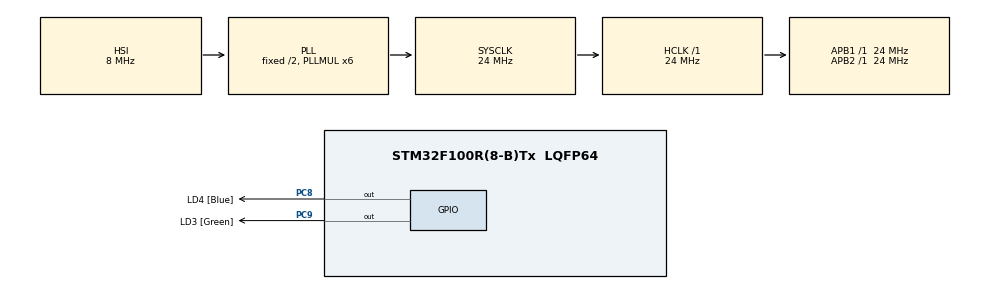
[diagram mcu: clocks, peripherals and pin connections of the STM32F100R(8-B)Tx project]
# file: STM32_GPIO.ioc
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Mcu.Family=STM32F1
Mcu.Name=STM32F100R(8-B)Tx
Mcu.Package=LQFP64
NVIC.PriorityGroup=NVIC_PRIORITYGROUP_4
PA0-WKUP.Signal=SYS_WKUP
PA13.GPIO_Label=TMS_SWDIO
PA13.Signal=SYS_JTMS-SWDIO
PA14.GPIO_Label=TCK_SWCLK
PA14.Signal=SYS_JTCK-SWCLK
PC14-OSC32_IN.Signal=RCC_OSC32_IN
PC15-OSC32_OUT.Signal=RCC_OSC32_OUT
PC8.GPIO_Label=LD4 [Blue]
PC8.Signal=GPIO_Output
PC9.GPIO_Label=LD3 [Green]
PC9.Signal=GPIO_Output
ProjectManager.HeapSize=0x200
ProjectManager.StackSize=0x400
ProjectManager.TargetToolchain=MDK-ARM V5.32
RCC.AHBFreq_Value=24000000
RCC.APB1Freq_Value=24000000
RCC.APB1TimFreq_Value=24000000
RCC.APB2Freq_Value=24000000
RCC.APB2TimFreq_Value=24000000
RCC.HCLKFreq_Value=24000000
RCC.PLLMUL=RCC_PLL_MUL6
RCC.SYSCLKFreq_VALUE=24000000
RCC.SYSCLKSource=RCC_SYSCLKSOURCE_PLLCLK
VP_SYS_VS_ND.Mode=No_Debug
board=STM32VLDISCOVERY

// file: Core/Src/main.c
/*
 *
 *   Created on: 07.05.2023
 *
 *   Author: Metehan Kemal KAYAALP
 *
 *
 */
/**
  ******************************************************************************
  * @file           : main.c
  * @brief          : Main program body
  ******************************************************************************
  * @attention
  *
  * Copyright (c) 2023 STMicroelectronics.
  * All rights reserved.
  *
  * This software is licensed under terms that can be found in the LICENSE file
  * in the root directory of this software component.
  * If no LICENSE file comes with this software, it is provided AS-IS.
  *
  ******************************************************************************
  */
/* USER CODE END Header */

#include "main.h"

/* USER CODE BEGIN Includes */

#include "leddriver.h"
#include "buttondriver.h"

/* USER CODE END Includes */

void SystemClock_Config(void);
static void MX_GPIO_Init(void);

int main(void)
{

  /* MCU Configuration--------------------------------------------------------*/

  /* Reset of all peripherals, Initializes the Flash interface and the Systick. */
  HAL_Init();

  /* Configure the system clock */
  SystemClock_Config();

  /* Initialize all configured peripherals */
  //MX_GPIO_Init();
  /* USER CODE BEGIN 2 */
	leddriver_init();
	buttondriver_init();

  /* USER CODE END 2 */

  /* Infinite loop */
  while (1)
  {
		if (buttondriver_get_state() == 1){
		leddriver_on();
		HAL_Delay(50);
		leddriver_off();
		HAL_Delay(50);
		}

  }
}

void SystemClock_Config(void)
{
  RCC_OscInitTypeDef RCC_OscInitStruct = {0};
  RCC_ClkInitTypeDef RCC_ClkInitStruct = {0};

  /** Initializes the RCC Oscillators according to the specified parameters
  * in the RCC_OscInitTypeDef structure.
  */
  RCC_OscInitStruct.OscillatorType = RCC_OSCILLATORTYPE_HSI;
  RCC_OscInitStruct.HSIState = RCC_HSI_ON;
  RCC_OscInitStruct.HSICalibrationValue = RCC_HSICALIBRATION_DEFAULT;
  RCC_OscInitStruct.PLL.PLLState = RCC_PLL_ON;
  RCC_OscInitStruct.PLL.PLLSource = RCC_PLLSOURCE_HSI_DIV2;
  RCC_OscInitStruct.PLL.PLLMUL = RCC_PLL_MUL6;
  if (HAL_RCC_OscConfig(&RCC_OscInitStruct) != HAL_OK)
  {
    Error_Handler();
  }

  /** Initializes the CPU, AHB and APB buses clocks
  */
  RCC_ClkInitStruct.ClockType = RCC_CLOCKTYPE_HCLK|RCC_CLOCKTYPE_SYSCLK
                              |RCC_CLOCKTYPE_PCLK1|RCC_CLOCKTYPE_PCLK2;
  RCC_ClkInitStruct.SYSCLKSource = RCC_SYSCLKSOURCE_PLLCLK;
  RCC_ClkInitStruct.AHBCLKDivider = RCC_SYSCLK_DIV1;
  RCC_ClkInitStruct.APB1CLKDivider = RCC_HCLK_DIV1;
  RCC_ClkInitStruct.APB2CLKDivider = RCC_HCLK_DIV1;

  if (HAL_RCC_ClockConfig(&RCC_ClkInitStruct, FLASH_LATENCY_0) != HAL_OK)
  {
    Error_Handler();
  }
}

static void MX_GPIO_Init(void)
{
  GPIO_InitTypeDef GPIO_InitStruct = {0};

  /* GPIO Ports Clock Enable */
  __HAL_RCC_GPIOC_CLK_ENABLE();
  __HAL_RCC_GPIOA_CLK_ENABLE();

  /*Configure GPIO pin Output Level */
  HAL_GPIO_WritePin(GPIOC, LD4_Pin|LD3_Pin, GPIO_PIN_RESET);

  /*Configure GPIO pins : LD4_Pin LD3_Pin */
  GPIO_InitStruct.Pin = LD4_Pin|LD3_Pin;
  GPIO_InitStruct.Mode = GPIO_MODE_OUTPUT_PP;
  GPIO_InitStruct.Pull = GPIO_NOPULL;
  GPIO_InitStruct.Speed = GPIO_SPEED_FREQ_LOW;
  HAL_GPIO_Init(GPIOC, &GPIO_InitStruct);

}

void Error_Handler(void)
{
  __disable_irq();
  while (1)
  {
  }
}
